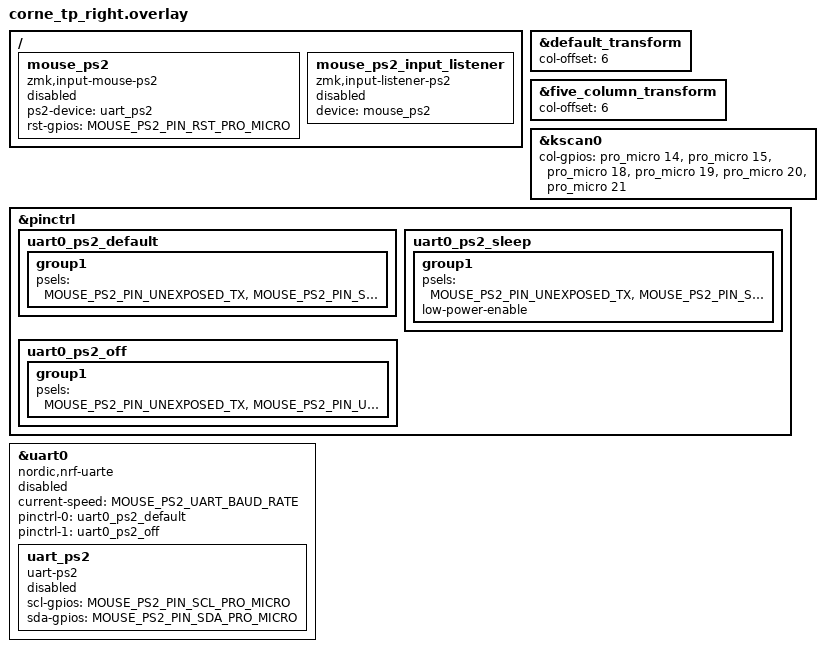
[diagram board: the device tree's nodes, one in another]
/*
 * Copyright (c) 2020 Pete Johanson
 *
 * SPDX-License-Identifier: MIT
 */

#include "corne_tp.dtsi"

&default_transform {
    col-offset = <6>;
};

&five_column_transform {
    col-offset = <6>;
};

&kscan0 {
    col-gpios
        = <&pro_micro 14 GPIO_ACTIVE_HIGH>
        , <&pro_micro 15 GPIO_ACTIVE_HIGH>
        , <&pro_micro 18 GPIO_ACTIVE_HIGH>
        , <&pro_micro 19 GPIO_ACTIVE_HIGH>
        , <&pro_micro 20 GPIO_ACTIVE_HIGH>
        , <&pro_micro 21 GPIO_ACTIVE_HIGH>;
};

#define MOUSE_PS2_DRIVER_UART
#define MOUSE_PS2_PIN_SCL_PRO_MICRO <&pro_micro 3 GPIO_ACTIVE_HIGH>
#define MOUSE_PS2_PIN_SDA_PRO_MICRO <&pro_micro 2 GPIO_ACTIVE_HIGH>
#define MOUSE_PS2_PIN_RST_PRO_MICRO <&pro_micro 9 GPIO_ACTIVE_HIGH>
#define MOUSE_PS2_PIN_SDA_PINCTRL <NRF_PSEL(UART_RX, 0, 2)>
#define MOUSE_PS2_UART_BAUD_RATE <14400>

#define MOUSE_PS2_PIN_UNEXPOSED_TX <NRF_PSEL(UART_TX, 0, 27)>
#define MOUSE_PS2_PIN_UNEXPOSED_RX <NRF_PSEL(UART_RX, 0, 28)>
#define MOUSE_PS2_DT_PRESENT

&pinctrl {
    uart0_ps2_default: uart0_ps2_default {
        group1 {
            psels = MOUSE_PS2_PIN_UNEXPOSED_TX, MOUSE_PS2_PIN_SDA_PINCTRL;
        };
    };
    uart0_ps2_sleep: uart0_ps2_sleep {
        group1 {
            psels = MOUSE_PS2_PIN_UNEXPOSED_TX, MOUSE_PS2_PIN_SDA_PINCTRL;
            low-power-enable;
        };
    };
    uart0_ps2_off: uart0_ps2_off {
        group1 {
            psels = MOUSE_PS2_PIN_UNEXPOSED_TX, MOUSE_PS2_PIN_UNEXPOSED_RX;
        };
    };
};

&uart0 {
    status = "disabled";
    compatible = "nordic,nrf-uarte";
    current-speed = MOUSE_PS2_UART_BAUD_RATE;
    pinctrl-0 = <&uart0_ps2_default>;
    pinctrl-1 = <&uart0_ps2_off>;
    pinctrl-names = "default", "sleep";

    uart_ps2: uart_ps2 {
        status = "disabled";
        compatible = "uart-ps2";
        scl-gpios = MOUSE_PS2_PIN_SCL_PRO_MICRO;
        sda-gpios = MOUSE_PS2_PIN_SDA_PRO_MICRO;
    };
};

/ {
    mouse_ps2: mouse_ps2 {
        status = "disabled";
        compatible = "zmk,input-mouse-ps2";
        ps2-device = <&uart_ps2>;
        rst-gpios = MOUSE_PS2_PIN_RST_PRO_MICRO;
    };

    mouse_ps2_input_listener: mouse_ps2_input_listener {
        compatible = "zmk,input-listener-ps2";
        status = "disabled";
        device = <&mouse_ps2>;
    };
};
